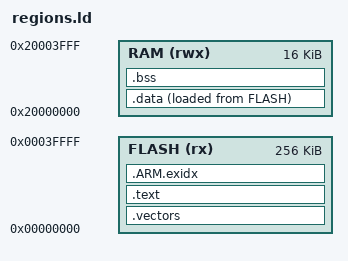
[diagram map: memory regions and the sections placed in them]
/* SPDX-License-Identifier: Apache-2.0 */
/*
 * Generated by emb-hwgen 0.1.0, schema v0. Do not edit: change the
 * description and run hw/gen/emb-hwgen.py generate --board boards/bbc/microbit (HW-003).
 * Inputs (SHA-256):
 *   arch/cortex_m/arch.yaml
 *     9bef19ece048832364390ddf6129944c8e8828b6cdd2f6a25d64613b14130c2b
 *   boards/bbc/microbit/board.yaml
 *     cda18387661b10addd5ad6e724192d5c9e675a842bc3add652494f8918c057e2
 *   soc/nordic/nrf51/nrf51.yaml
 *     4486cb5e81c14213d4029ff71a34757e3841fd70b9b16b9d5d2d3959650e26a7
 *   soc/nordic/nrf51/nrf51822.yaml
 *     530ed388d56cb9c222217ad7676b994c6fb833522a477dd618ae2900f441fe3e
 */
/* Linker script for microbit (nRF51822): the app partition in FLASH, RAM from sram. The kernel's registration
 * tables are bracketed by name (SPEC-001 §6.4, HW-006). */
ENTRY(embn_cm_reset)

MEMORY
{
  FLASH (rx)  : ORIGIN = 0x00000000, LENGTH = 256K
  RAM   (rwx) : ORIGIN = 0x20000000, LENGTH = 16K
}

SECTIONS
{
  /* the vector table, then any block the SoC's boot ROM looks for near the image's start
     (the RP2350's IMAGE_DEF, A79) */
  .vectors : { KEEP(*(.vectors)) KEEP(*(.emb_boot_block)) } > FLASH

  .text : {
    *(.text .text.*)
    *(.rodata .rodata.*)
    . = ALIGN(16); /* the table entries' own alignment (sizeof(void *) * 4) */
    __start_emb_init_table = .;
    KEEP(*(emb_init_table))
    __stop_emb_init_table = .;
    . = ALIGN(16);
    __start_emb_test_table = .;
    KEEP(*(emb_test_table))
    __stop_emb_test_table = .;
    . = ALIGN(8);
  } > FLASH

  .ARM.exidx : { *(.ARM.exidx* .gnu.linkonce.armexidx.*) } > FLASH

  __data_load = LOADADDR(.data);
  .data : ALIGN(8) {
    __data_start = .;
    *(.data .data.*)
    . = ALIGN(8);
    __data_end = .;
  } > RAM AT > FLASH

  .bss (NOLOAD) : ALIGN(8) {
    __bss_start = .;
    *(.bss .bss.* COMMON)
    . = ALIGN(8);
    __bss_end = .;
  } > RAM

  end = .;
  /* the crash record's memory (SPEC-015 §4, A73): above the stack and outside every loaded
     segment, so neither startup nor a loader's reset clears it */
  __emb_retained_end = ORIGIN(RAM) + LENGTH(RAM);
  __emb_retained_start = __emb_retained_end - 192;
  /* below it, 32 bytes the test framework keeps across the resets of its fault checks (A89) */
  __emb_test_retained_end = __emb_retained_start;
  __emb_test_retained_start = __emb_test_retained_end - 32;
  __stack_top = __emb_test_retained_start;
}
